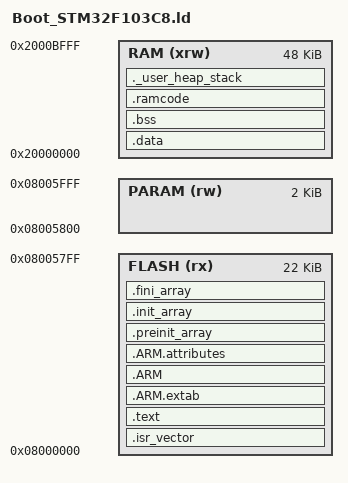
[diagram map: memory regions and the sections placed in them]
ENTRY(Reset_Handler)

_estack = 0x2000C000;

_Min_Heap_Size  = 0;
_Min_Stack_Size = 0x200;

MEMORY
{
  FLASH (rx)  : ORIGIN = 0x08000000, LENGTH = 22K
  PARAM (rw)  : ORIGIN = 0x08005800, LENGTH = 2K
  RAM   (xrw) : ORIGIN = 0x20000000, LENGTH = 48K
}

SECTIONS
{
  .isr_vector :
  {
    . = ALIGN(4);
    KEEP(*(.isr_vector))
    . = ALIGN(4);
  } >FLASH

  .text :
  {
    . = ALIGN(4);
    *(.text)
    *(.text*)
    *(.rodata)
    *(.rodata*)
    *(.glue_7)
    *(.glue_7t)
    KEEP (*(.init))
    KEEP (*(.fini))
    . = ALIGN(4);
    _etext = .;
  } >FLASH

  .ARM.extab : { *(.ARM.extab* .gnu.linkonce.armextab.*) } >FLASH
  .ARM : {
    __exidx_start = .;
    *(.ARM.exidx*)
    __exidx_end = .;
  } >FLASH

  .ARM.attributes : { *(.ARM.attributes) } > FLASH

  .preinit_array :
  {
    PROVIDE_HIDDEN (__preinit_array_start = .);
    KEEP (*(.preinit_array*))
    PROVIDE_HIDDEN (__preinit_array_end = .);
  } >FLASH

  .init_array :
  {
    PROVIDE_HIDDEN (__init_array_start = .);
    KEEP (*(SORT(.init_array.*)))
    KEEP (*(.init_array*))
    PROVIDE_HIDDEN (__init_array_end = .);
  } >FLASH

  .fini_array :
  {
    PROVIDE_HIDDEN (__fini_array_start = .);
    KEEP (*(.fini_array*))
    KEEP (*(SORT(.fini_array.*)))
    PROVIDE_HIDDEN (__fini_array_end = .);
  } >FLASH

  _sidata = .;

  .data : AT ( _sidata )
  {
    . = ALIGN(4);
    _sdata = .;
    *(.data)
    *(.data*)
    . = ALIGN(4);
    _edata = .;
  } >RAM

  . = ALIGN(4);
  .bss :
  {
    _sbss = .;
    __bss_start__ = _sbss;
    *(.bss)
    *(.bss*)
    *(COMMON)
    . = ALIGN(4);
    _ebss = .;
    __bss_end__ = _ebss;
  } >RAM

  _siramcode = LOADADDR(.ramcode);

  .ramcode : AT ( _sidata + SIZEOF(.data) )
  {
    . = ALIGN(4);
    _sramcode = .;
    *(.ramcode*)
    . = ALIGN(4);
    _eramcode = .;
  } >RAM

  PROVIDE ( end = _ebss );
  PROVIDE ( _end = _ebss );

  ._user_heap_stack :
  {
    . = ALIGN(4);
    . = . + _Min_Heap_Size;
    . = . + _Min_Stack_Size;
    . = ALIGN(4);
  } >RAM

  /DISCARD/ :
  {
    *(.ARM.exidx*)
  }
}
